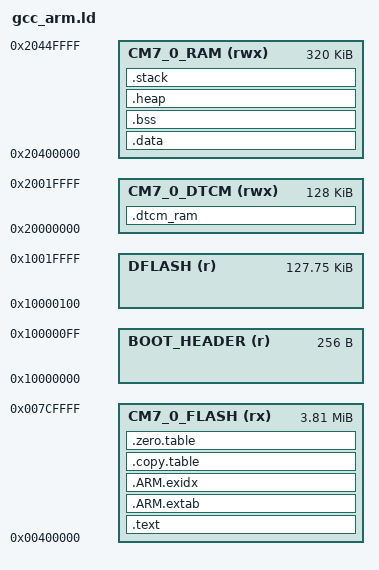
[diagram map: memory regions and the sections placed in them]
/*---------------------------------------------------------------------------
 * Name:    S32K3xx.ld
 * Purpose: GNU Linker Script for S32K3xx based device
 *---------------------------------------------------------------------------*/

MEMORY
{
  BOOT_HEADER    (r)   : ORIGIN = 0x10000000, LENGTH = 0x00000100

  CM7_0_FLASH    (rx)  : ORIGIN = 0x00400000, LENGTH = 0x003D0000  /* 0x00400000 */
  CM7_0_RAM      (rwx) : ORIGIN = 0x20400000, LENGTH = 0x00050000  /* (2 x 160kB) */
  CM7_0_DTCM     (rwx) : ORIGIN = 0x20000000, LENGTH = 0x00020000

  DFLASH         (r)   : ORIGIN = 0x10000100, LENGTH = 0x0001FF00
}

REGION_ALIAS("FLASH", CM7_0_FLASH);                  /* set ALIAS to used core */
REGION_ALIAS("RAM",   CM7_0_RAM);
REGION_ALIAS("DTCM",  CM7_0_DTCM);


/* Linker script to place sections and symbol values. Should be used together
 * with other linker script that defines memory regions FLASH and RAM.
 * It references following symbols, which must be defined in code:
 *   Reset_Handler : Entry of reset handler
 *
 * It defines following symbols, which code can use without definition:
 *   __exidx_start
 *   __exidx_end
 *   __copy_table_start__
 *   __copy_table_end__
 *   __zero_table_start__
 *   __zero_table_end__
 *   __etext
 *   __data_start__
 *   __preinit_array_start
 *   __preinit_array_end
 *   __init_array_start
 *   __init_array_end
 *   __fini_array_start
 *   __fini_array_end
 *   __data_end__
 *   __bss_start__
 *   __bss_end__
 *   __end__
 *   end
 *   __HeapLimit
 *   __StackLimit
 *   __StackTop
 *   __stack
 */
ENTRY(Reset_Handler)

SECTIONS
{
  .dtcm_ram :
  {
    *(.dtcm_ram)
  } > DTCM

/*
  .bootheader :
  {
    KEEP(*(.bootheader))
  } > BOOT_HEADER
*/
  .text :
  {
    KEEP(*(.vectors))
    *(.text*)

    KEEP(*(.init))
    KEEP(*(.fini))

    /* .ctors */
    *crtbegin.o(.ctors)
    *crtbegin?.o(.ctors)
    *(EXCLUDE_FILE(*crtend?.o *crtend.o) .ctors)
    *(SORT(.ctors.*))
    *(.ctors)

    /* .dtors */
    *crtbegin.o(.dtors)
    *crtbegin?.o(.dtors)
    *(EXCLUDE_FILE(*crtend?.o *crtend.o) .dtors)
    *(SORT(.dtors.*))
    *(.dtors)

    *(.rodata*)

    KEEP(*(.eh_frame*))
  } > FLASH

  .ARM.extab :
  {
    *(.ARM.extab* .gnu.linkonce.armextab.*)
  } > FLASH

  __exidx_start = .;
  .ARM.exidx :
  {
    *(.ARM.exidx* .gnu.linkonce.armexidx.*)
  } > FLASH
  __exidx_end = .;

  .copy.table :
  {
    . = ALIGN(4);
    __copy_table_start__ = .;

    LONG (__etext)
    LONG (__data_start__)
    LONG ((__data_end__ - __data_start__) / 4)

    /* Add each additional data section here */
/*
    LONG (__etext2)
    LONG (__data2_start__)
    LONG ((__data2_end__ - __data2_start__) / 4)
*/
    __copy_table_end__ = .;
  } > FLASH

  .zero.table :
  {
    . = ALIGN(4);
    __zero_table_start__ = .;
    /* Add each additional bss section here */
/*
    LONG (__bss2_start__)
    LONG ((__bss2_end__ - __bss2_start__) / 4)
*/
    __zero_table_end__ = .;
  } > FLASH

  __etext = ALIGN (4);

  .data : AT (__etext)
  {
    __data_start__ = .;
    *(vtable)
    *(.data)
    *(.data.*)

    . = ALIGN(4);
    /* preinit data */
    PROVIDE_HIDDEN (__preinit_array_start = .);
    KEEP(*(.preinit_array))
    PROVIDE_HIDDEN (__preinit_array_end = .);

    . = ALIGN(4);
    /* init data */
    PROVIDE_HIDDEN (__init_array_start = .);
    KEEP(*(SORT(.init_array.*)))
    KEEP(*(.init_array))
    PROVIDE_HIDDEN (__init_array_end = .);

    . = ALIGN(4);
    /* finit data */
    PROVIDE_HIDDEN (__fini_array_start = .);
    KEEP(*(SORT(.fini_array.*)))
    KEEP(*(.fini_array))
    PROVIDE_HIDDEN (__fini_array_end = .);

    KEEP(*(.jcr*))
    . = ALIGN(4);
    /* All data end */
    __data_end__ = .;

  } > RAM

  .bss :
  {
    . = ALIGN(4);
    __bss_start__ = .;
    *(.bss)
    *(.bss.*)
    *(COMMON)
    . = ALIGN(4);
    __bss_end__ = .;
  } > RAM AT > RAM

  .heap (COPY) :
  {
    . = ALIGN(8);
    __end__ = .;
    PROVIDE(end = .);
    . = . + __HEAP_SIZE;
    . = ALIGN(8);
    __HeapLimit = .;
  } > RAM

  .stack (ORIGIN(RAM) + LENGTH(RAM) - __STACK_SIZE) (COPY) :
  {
    . = ALIGN(8);
    __StackLimit = .;
    . = . + __STACK_SIZE;
    . = ALIGN(8);
    __StackTop = .;
  } > RAM
  PROVIDE(__stack = __StackTop);

  /* Check if data + heap + stack exceeds RAM limit */
  ASSERT(__StackLimit >= __HeapLimit, "region RAM overflowed with stack")
}
